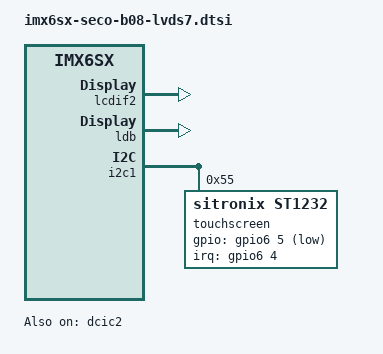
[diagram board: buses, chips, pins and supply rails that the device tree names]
/*
 * Copyright (C) 2015 Jasbir Matharu
 * Author: Giuseppe Pagano <giuseppe.pagano@seco.com>
 *
 * This program is free software; you can redistribute it and/or modify
 * it under the terms of the GNU General Public License version 2 as
 * published by the Free Software Foundation.
 */

// / {
//         regulators {
//                reg_lcd_bl: lcd_bl {
//                        status = "okay";
//                };
//
//		reg_lcd_panel_on: lcd_pon {
//			status = "okay";
//		};
//         };
// };

&lcdif2 {
	display = <&display1>;
	disp-dev = "ldb";
	lcd-supply = <&reg_lcd_panel_on>;
	status = "okay";

	display1: display {
		bits-per-pixel = <16>;
		bus-width = <18>;
	};
};

//	lcd-supply = <&reg_lcd_bl
//                      &reg_lcd_panel_on>;

&ldb {
	pinctrl-names = "default";
	pinctrl-0 = <&pinctrl_ldb_0>;
	status = "okay";

	lvds-channel@0 {
		fsl,data-mapping = "spwg";
		fsl,data-width = <18>;
		crtc = "lcdif2";
		status = "okay";
		
		display-timings {
			native-mode = <&timing2>;
			timing2: LDB-WVGA {
				clock-frequency = <33660000>;
				hactive = <800>;
				vactive = <480>;
				hback-porch = <56>;
				hfront-porch = <50>;
				vback-porch = <23>;
				vfront-porch = <20>;
				hsync-len = <150>;
				vsync-len = <2>;
			};
		};
	};
};

&i2c1 {
	touchscreen: st1232@55 {
		pinctrl-names = "default";
		pinctrl-0 = <&pinctrl_st1232>;
		compatible = "sitronix,st1232";
		reg = <0x55>;
		interrupt-parent = <&gpio6>;
		interrupts = <4 IRQ_TYPE_LEVEL_LOW>;
		gpios = <&gpio6 5 GPIO_ACTIVE_LOW>;
	};
};


&dcic2 {
	dcic_id = <1>;
	dcic_mux = "dcic-lvds";
	status = "okay";
};
